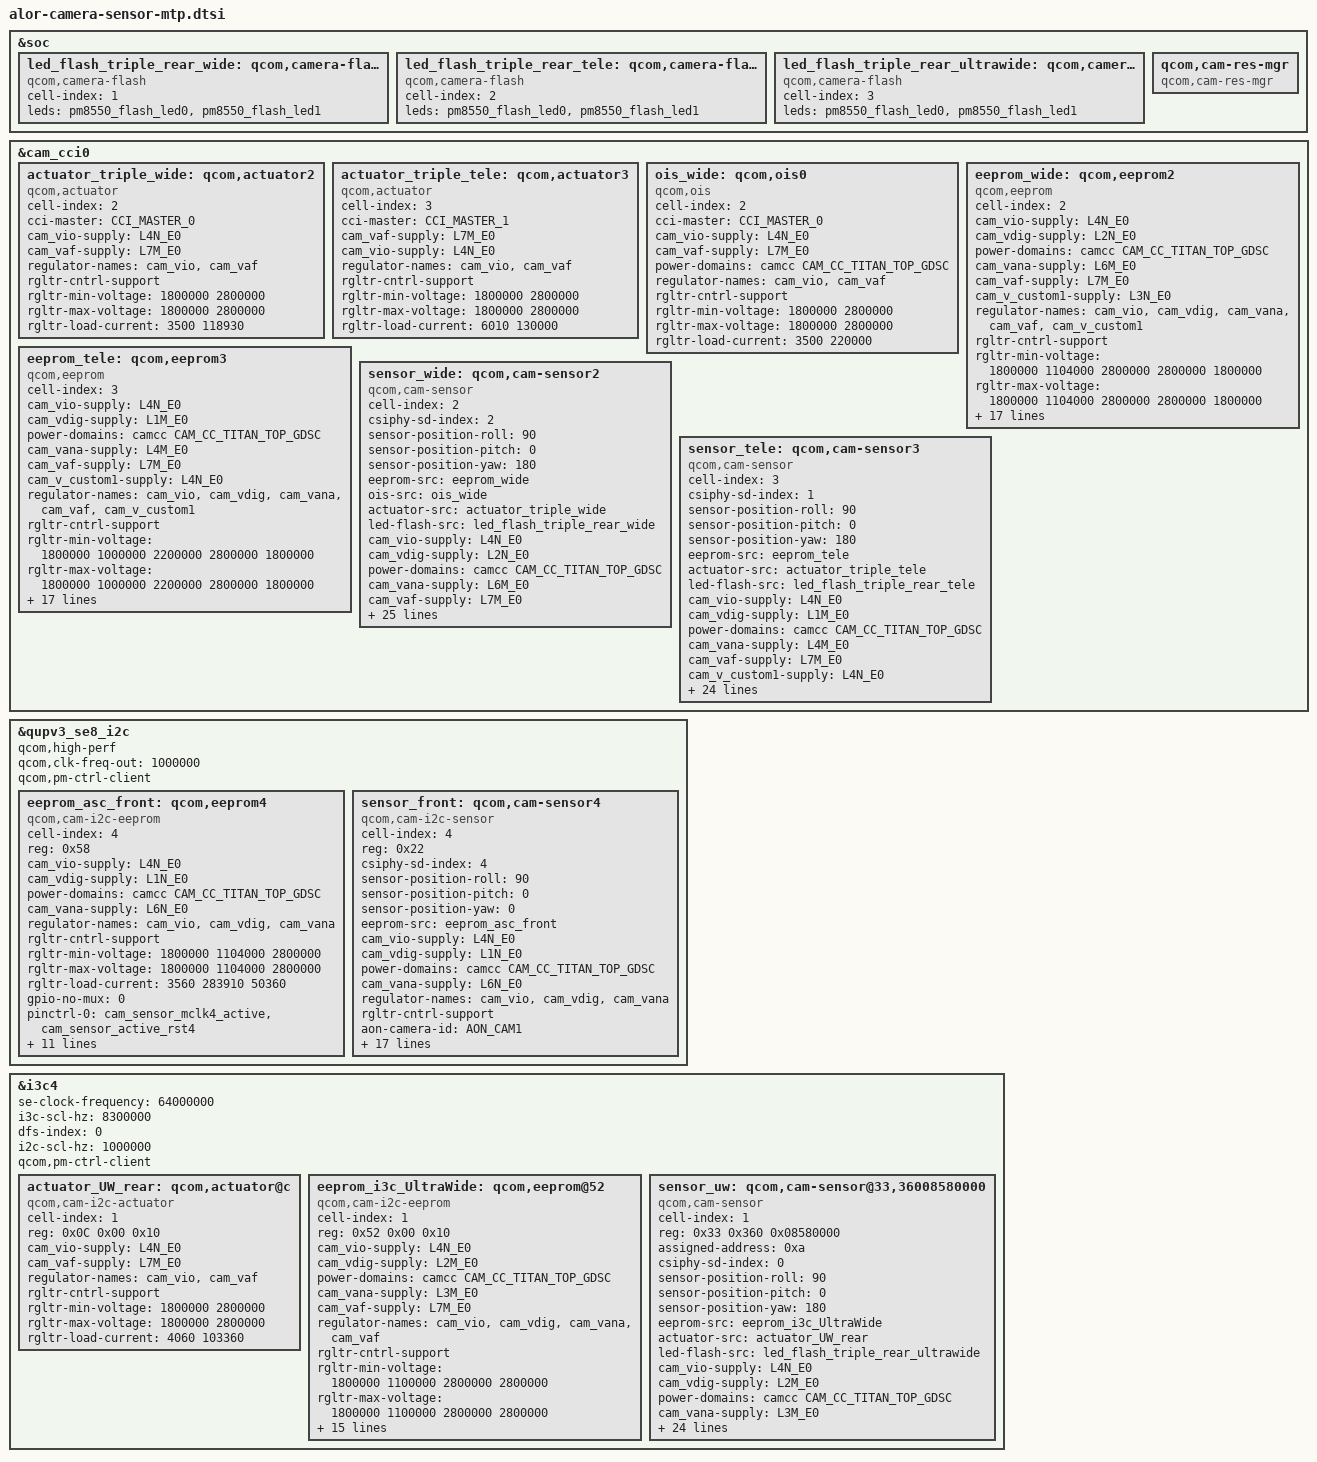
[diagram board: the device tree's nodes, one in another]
// SPDX-License-Identifier: BSD-3-Clause-Clear
/*
 * Copyright (c) Qualcomm Technologies, Inc. and/or its subsidiaries.
 */

#include <dt-bindings/msm-camera.h>

&soc {
	led_flash_triple_rear_wide: qcom,camera-flash1 {
		cell-index = <1>;
		compatible = "qcom,camera-flash";
		leds = <&pm8550_flash_led0 &pm8550_flash_led1>;
		status = "ok";
	};

	led_flash_triple_rear_tele: qcom,camera-flash2 {
		cell-index = <2>;
		compatible = "qcom,camera-flash";
		leds = <&pm8550_flash_led0 &pm8550_flash_led1>;
		status = "ok";
	};

	led_flash_triple_rear_ultrawide: qcom,camera-flash3 {
		cell-index = <3>;
		compatible = "qcom,camera-flash";
		leds = <&pm8550_flash_led0 &pm8550_flash_led1>;
		status = "ok";
	};

	qcom,cam-res-mgr {
		compatible = "qcom,cam-res-mgr";
		status = "ok";
	};
};

&cam_cci0 {
	actuator_triple_wide: qcom,actuator2 {
		cell-index = <2>;
		compatible = "qcom,actuator";
		cci-master = <CCI_MASTER_0>;
		cam_vio-supply = <&L4N_E0>;
		cam_vaf-supply = <&L7M_E0>;
		regulator-names = "cam_vio","cam_vaf";
		rgltr-cntrl-support;
		rgltr-min-voltage = <1800000 2800000>;
		rgltr-max-voltage = <1800000 2800000>;
		rgltr-load-current = <3500 118930>;
		status = "ok";
	};

	actuator_triple_tele: qcom,actuator3 {
		cell-index = <3>;
		compatible = "qcom,actuator";
		cci-master = <CCI_MASTER_1>;
		cam_vaf-supply = <&L7M_E0>;
		cam_vio-supply = <&L4N_E0>;
		regulator-names = "cam_vio","cam_vaf";
		rgltr-cntrl-support;
		rgltr-min-voltage = <1800000 2800000>;
		rgltr-max-voltage = <1800000 2800000>;
		rgltr-load-current = <6010 130000>;
		status = "ok";
	};

	ois_wide: qcom,ois0 {
		cell-index = <2>;
		compatible = "qcom,ois";
		cci-master = <CCI_MASTER_0>;
		cam_vio-supply = <&L4N_E0>;
		cam_vaf-supply = <&L7M_E0>;
		power-domains = <&camcc CAM_CC_TITAN_TOP_GDSC>;
		regulator-names = "cam_vio","cam_vaf";
		rgltr-cntrl-support;
		rgltr-min-voltage = <1800000 2800000>;
		rgltr-max-voltage = <1800000 2800000>;
		rgltr-load-current = <3500 220000>;
		status = "ok";
	};

	eeprom_wide: qcom,eeprom2 {
		cell-index = <2>;
		compatible = "qcom,eeprom";
		cam_vio-supply = <&L4N_E0>;
		cam_vdig-supply = <&L2N_E0>;
		power-domains = <&camcc CAM_CC_TITAN_TOP_GDSC>;
		cam_vana-supply = <&L6M_E0>;
		cam_vaf-supply = <&L7M_E0>;
		cam_v_custom1-supply = <&L3N_E0>;
		regulator-names = "cam_vio", "cam_vdig", "cam_vana",
			"cam_vaf", "cam_v_custom1";
		rgltr-cntrl-support;
		rgltr-min-voltage = <1800000 1104000 2800000 2800000 1800000>;
		rgltr-max-voltage = <1800000 1104000 2800000 2800000 1800000>;
		rgltr-load-current = <3500 913200 91430 118930 63100>;
		gpio-no-mux = <0>;
		pinctrl-names = "cam_default", "cam_suspend";
		pinctrl-0 = <&cam_sensor_mclk2_active
				 &cam_sensor_active_rst2>;
		pinctrl-1 = <&cam_sensor_mclk2_suspend
				 &cam_sensor_suspend_rst2>;
		gpios = <&tlmm 91 0>,
			<&tlmm 90 0>;
		gpio-reset = <1>;
		gpio-req-tbl-num = <0 1>;
		gpio-req-tbl-flags = <1 0>;
		gpio-req-tbl-label = "CAMIF_MCLK2",
					"CAM_RESET2";
		cci-master = <CCI_MASTER_0>;
		clocks = <&cambistmclkcc CAM_BIST_MCLK_CC_MCLK2_CLK>;
		clock-names = "cam_clk";
		clock-cntl-level = "nominal";
		clock-rates = <24000000>;
		status = "ok";
	};

	eeprom_tele: qcom,eeprom3 {
		cell-index = <3>;
		compatible = "qcom,eeprom";
		cam_vio-supply = <&L4N_E0>;
		cam_vdig-supply = <&L1M_E0>;
		power-domains = <&camcc CAM_CC_TITAN_TOP_GDSC>;
		cam_vana-supply = <&L4M_E0>;
		cam_vaf-supply = <&L7M_E0>;
		cam_v_custom1-supply = <&L4N_E0>;
		regulator-names = "cam_vio", "cam_vdig",
			"cam_vana", "cam_vaf", "cam_v_custom1";
		rgltr-cntrl-support;
		rgltr-min-voltage = <1800000 1000000 2200000 2800000 1800000>;
		rgltr-max-voltage = <1800000 1000000 2200000 2800000 1800000>;
		rgltr-load-current = <6010 274060 86550 130000 2580>;
		gpio-no-mux = <0>;
		pinctrl-names = "cam_default", "cam_suspend";
		pinctrl-0 = <&cam_sensor_mclk0_active
				 &cam_sensor_active_rst1>;
		pinctrl-1 = <&cam_sensor_mclk0_suspend
				 &cam_sensor_suspend_rst1>;
		gpios = <&tlmm 89 0>,
			<&tlmm 163 0>;
		gpio-reset = <1>;
		gpio-req-tbl-num = <0 1>;
		gpio-req-tbl-flags = <1 0>;
		gpio-req-tbl-label = "CAMIF_MCLK0",
					"CAM_RESET1";
		cci-master = <CCI_MASTER_1>;
		clocks = <&cambistmclkcc CAM_BIST_MCLK_CC_MCLK0_CLK>;
		clock-names = "cam_clk";
		clock-cntl-level = "nominal";
		clock-rates = <24000000>;
		status = "ok";
	};

	// Wide
	sensor_wide: qcom,cam-sensor2 {
		cell-index = <2>;
		compatible = "qcom,cam-sensor";
		csiphy-sd-index = <2>;
		sensor-position-roll = <90>;
		sensor-position-pitch = <0>;
		sensor-position-yaw = <180>;
		eeprom-src = <&eeprom_wide>;
		ois-src = <&ois_wide>;
		actuator-src = <&actuator_triple_wide>;
		led-flash-src = <&led_flash_triple_rear_wide>;
		cam_vio-supply = <&L4N_E0>;
		cam_vdig-supply = <&L2N_E0>;
		power-domains = <&camcc CAM_CC_TITAN_TOP_GDSC>;
		cam_vana-supply = <&L6M_E0>;
		cam_vaf-supply = <&L7M_E0>;
		cam_v_custom1-supply = <&L3N_E0>;
		regulator-names = "cam_vio", "cam_vdig", "cam_vana",
			"cam_vaf", "cam_v_custom1";
		rgltr-cntrl-support;
		rgltr-min-voltage = <1800000 1104000 2800000 2800000 1800000>;
		rgltr-max-voltage = <1800000 1104000 2800000 2800000 1800000>;
		rgltr-load-current = <3500 913200 91430 118930 63100>;
		gpio-no-mux = <0>;
		pinctrl-names = "cam_default", "cam_suspend";
		pinctrl-0 = <&cam_sensor_mclk2_active
				 &cam_sensor_active_rst2>;
		pinctrl-1 = <&cam_sensor_mclk2_suspend
				 &cam_sensor_suspend_rst2>;
		gpios = <&tlmm 91 0>,
			<&tlmm 90 0>;
		gpio-reset = <1>;
		gpio-req-tbl-num = <0 1>;
		gpio-req-tbl-flags = <1 0>;
		gpio-req-tbl-label = "CAMIF_MCLK2",
					"CAM_RESET2";
		cci-master = <CCI_MASTER_0>;
		clocks = <&cambistmclkcc CAM_BIST_MCLK_CC_MCLK2_CLK>;
		clock-names = "cam_clk";
		clock-cntl-level = "nominal";
		clock-rates = <24000000>;
		status = "ok";
	};

	// Tele
	sensor_tele: qcom,cam-sensor3 {
		cell-index = <3>;
		compatible = "qcom,cam-sensor";
		csiphy-sd-index = <1>;
		sensor-position-roll = <90>;
		sensor-position-pitch = <0>;
		sensor-position-yaw = <180>;
		eeprom-src = <&eeprom_tele>;
		actuator-src = <&actuator_triple_tele>;
		led-flash-src = <&led_flash_triple_rear_tele>;
		cam_vio-supply = <&L4N_E0>;
		cam_vdig-supply = <&L1M_E0>;
		power-domains = <&camcc CAM_CC_TITAN_TOP_GDSC>;
		cam_vana-supply = <&L4M_E0>;
		cam_vaf-supply = <&L7M_E0>;
		cam_v_custom1-supply = <&L4N_E0>;
		regulator-names = "cam_vio", "cam_vdig",
			"cam_vana", "cam_vaf", "cam_v_custom1";
		rgltr-cntrl-support;
		rgltr-min-voltage = <1800000 1000000 2200000 2800000 1800000>;
		rgltr-max-voltage = <1800000 1000000 2200000 2800000 1800000>;
		rgltr-load-current = <6010 274060 86550 130000 2580>;
		gpio-no-mux = <0>;
		pinctrl-names = "cam_default", "cam_suspend";
		pinctrl-0 = <&cam_sensor_mclk0_active
				 &cam_sensor_active_rst1>;
		pinctrl-1 = <&cam_sensor_mclk0_suspend
				 &cam_sensor_suspend_rst1>;
		gpios = <&tlmm 89 0>,
			<&tlmm 163 0>;
		gpio-reset = <1>;
		gpio-req-tbl-num = <0 1>;
		gpio-req-tbl-flags = <1 0>;
		gpio-req-tbl-label = "CAMIF_MCLK0",
					"CAM_RESET1";
		cci-master = <CCI_MASTER_1>;
		clocks = <&cambistmclkcc CAM_BIST_MCLK_CC_MCLK0_CLK>;
		clock-names = "cam_clk";
		clock-cntl-level = "nominal";
		clock-rates = <24000000>;
		status = "ok";
	};
};

&qupv3_se8_i2c{
	status = "ok";
	qcom,high-perf;
	qcom,clk-freq-out = <1000000>;
	qcom,pm-ctrl-client;

	eeprom_asc_front: qcom,eeprom4 {
		cell-index = <4>;
		reg = <0x58>;
		compatible = "qcom,cam-i2c-eeprom";
		cam_vio-supply = <&L4N_E0>;
		cam_vdig-supply = <&L1N_E0>;
		power-domains = <&camcc CAM_CC_TITAN_TOP_GDSC>;
		cam_vana-supply = <&L6N_E0>;
		regulator-names = "cam_vio", "cam_vdig", "cam_vana";
		rgltr-cntrl-support;
		rgltr-min-voltage = <1800000 1104000 2800000>;
		rgltr-max-voltage = <1800000 1104000 2800000>;
		rgltr-load-current = <3560 283910 50360>;
		gpio-no-mux = <0>;
		pinctrl-names = "cam_default", "cam_suspend";
		pinctrl-0 = <&cam_sensor_mclk4_active
				 &cam_sensor_active_rst4>;
		pinctrl-1 = <&cam_sensor_mclk4_suspend
				 &cam_sensor_suspend_rst4>;
		gpios = <&tlmm 93 0>,
			<&tlmm 3 0>;
		gpio-reset = <1>;
		gpio-req-tbl-num = <0 1>;
		gpio-req-tbl-flags = <1 0>;
		gpio-req-tbl-label = "CAMIF_MCLK4",
					"CAM_RESET4";
		clocks = <&cambistmclkcc CAM_BIST_MCLK_CC_MCLK4_CLK>;
		clock-names = "cam_clk";
		clock-cntl-level = "nominal";
		clock-rates = <24000000>;
		status = "ok";
	};

	// Front AON
	sensor_front: qcom,cam-sensor4 {
		cell-index = <4>;
		reg = <0x22>;
		compatible = "qcom,cam-i2c-sensor";
		csiphy-sd-index = <4>;
		sensor-position-roll = <90>;
		sensor-position-pitch = <0>;
		sensor-position-yaw = <0>;
		eeprom-src = <&eeprom_asc_front>;
		cam_vio-supply = <&L4N_E0>;
		cam_vdig-supply = <&L1N_E0>;
		power-domains = <&camcc CAM_CC_TITAN_TOP_GDSC>;
		cam_vana-supply = <&L6N_E0>;
		regulator-names = "cam_vio", "cam_vdig", "cam_vana";
		rgltr-cntrl-support;
		aon-camera-id = <AON_CAM1>;
		rgltr-min-voltage = <1800000 1104000 2800000>;
		rgltr-max-voltage = <1800000 1104000 2800000>;
		rgltr-load-current = <3560 283910 50360>;
		gpio-no-mux = <0>;
		pinctrl-names = "cam_default", "cam_suspend";
		pinctrl-0 = <&cam_sensor_mclk4_active
				 &cam_sensor_active_rst4>;
		pinctrl-1 = <&cam_sensor_mclk4_suspend
				 &cam_sensor_suspend_rst4>;
		gpios = <&tlmm 93 0>,
			<&tlmm 3 0>;
		gpio-reset = <1>;
		gpio-req-tbl-num = <0 1>;
		gpio-req-tbl-flags = <1 0>;
		gpio-req-tbl-label = "CAMIF_MCLK4",
					"CAM_RESET4";
		clocks = <&cambistmclkcc CAM_BIST_MCLK_CC_MCLK4_CLK>;
		clock-names = "cam_clk";
		clock-cntl-level = "nominal";
		clock-rates = <24000000>;
		status = "ok";
	};
};

&i3c4 {
	se-clock-frequency = <64000000>;
	i3c-scl-hz = <8300000>;
	dfs-index = <0>;
	i2c-scl-hz = <1000000>;
	qcom,pm-ctrl-client;
	status = "ok";

	actuator_UW_rear: qcom,actuator@c {
		cell-index = <1>;
		reg = <0x0C 0x00 0x10>;
		compatible = "qcom,cam-i2c-actuator";
		cam_vio-supply = <&L4N_E0>;
		cam_vaf-supply = <&L7M_E0>;
		regulator-names = "cam_vio","cam_vaf";
		rgltr-cntrl-support;
		rgltr-min-voltage = <1800000 2800000>;
		rgltr-max-voltage = <1800000 2800000>;
		rgltr-load-current = <4060 103360>;
		status = "ok";
	};

	eeprom_i3c_UltraWide: qcom,eeprom@52 {
		cell-index = <1>;
		reg = <0x52 0x00 0x10>;
		compatible = "qcom,cam-i2c-eeprom";
		cam_vio-supply = <&L4N_E0>;
		cam_vdig-supply = <&L2M_E0>;
		power-domains = <&camcc CAM_CC_TITAN_TOP_GDSC>;
		cam_vana-supply = <&L3M_E0>;
		cam_vaf-supply = <&L7M_E0>;
		regulator-names = "cam_vio", "cam_vdig", "cam_vana",
			"cam_vaf";
		rgltr-cntrl-support;
		rgltr-min-voltage = <1800000 1100000 2800000 2800000>;
		rgltr-max-voltage = <1800000 1100000 2800000 2800000>;
		rgltr-load-current = <4060 523640 107500 103360>;
		gpio-no-mux = <0>;
		pinctrl-names = "cam_default", "cam_suspend";
		pinctrl-0 = <&cam_sensor_mclk3_active
				&cam_sensor_active_rst3>;
		pinctrl-1 = <&cam_sensor_mclk3_suspend
				&cam_sensor_suspend_rst3>;
		gpios = <&tlmm 92 0>,
			<&tlmm 6 0>;
		gpio-reset = <1>;
		gpio-req-tbl-num = <0 1>;
		gpio-req-tbl-flags = <1 0>;
		gpio-req-tbl-label = "CAMIF_MCLK3",
					"CAM_RESET3";
		clocks = <&cambistmclkcc CAM_BIST_MCLK_CC_MCLK3_CLK>;
		clock-names = "cam_clk";
		clock-cntl-level = "nominal";
		clock-rates = <24000000>;
		status = "ok";
	};

	// Ultrawide
	sensor_uw: qcom,cam-sensor@33,36008580000 {
		cell-index = <1>;
		reg = <0x33 0x360 0x08580000>;
		assigned-address = <0xa>;
		compatible = "qcom,cam-sensor";
		csiphy-sd-index = <0>;
		sensor-position-roll = <90>;
		sensor-position-pitch = <0>;
		sensor-position-yaw = <180>;
		eeprom-src = <&eeprom_i3c_UltraWide>;
		actuator-src = <&actuator_UW_rear>;
		led-flash-src = <&led_flash_triple_rear_ultrawide>;
		cam_vio-supply = <&L4N_E0>;
		cam_vdig-supply = <&L2M_E0>;
		power-domains = <&camcc CAM_CC_TITAN_TOP_GDSC>;
		cam_vana-supply = <&L3M_E0>;
		cam_vaf-supply = <&L7M_E0>;
		regulator-names = "cam_vio", "cam_vdig", "cam_vana",
			"cam_vaf";
		rgltr-cntrl-support;
		i3c-target;
		rgltr-min-voltage = <1800000 1100000 2800000 2800000>;
		rgltr-max-voltage = <1800000 1100000 2800000 2800000>;
		rgltr-load-current = <4060 523640 107500 103360>;
		gpio-no-mux = <0>;
		pinctrl-names = "cam_default", "cam_suspend";
		pinctrl-0 = <&cam_sensor_mclk3_active
				&cam_sensor_active_rst3>;
		pinctrl-1 = <&cam_sensor_mclk3_suspend
				&cam_sensor_suspend_rst3>;
		gpios = <&tlmm 92 0>,
			<&tlmm 6 0>;
		gpio-reset = <1>;
		gpio-req-tbl-num = <0 1>;
		gpio-req-tbl-flags = <1 0>;
		gpio-req-tbl-label = "CAMIF_MCLK3",
					"CAM_RESET3";
		clocks = <&cambistmclkcc CAM_BIST_MCLK_CC_MCLK3_CLK>;
		clock-names = "cam_clk";
		clock-cntl-level = "nominal";
		clock-rates = <24000000>;
		status = "ok";
	};
};
